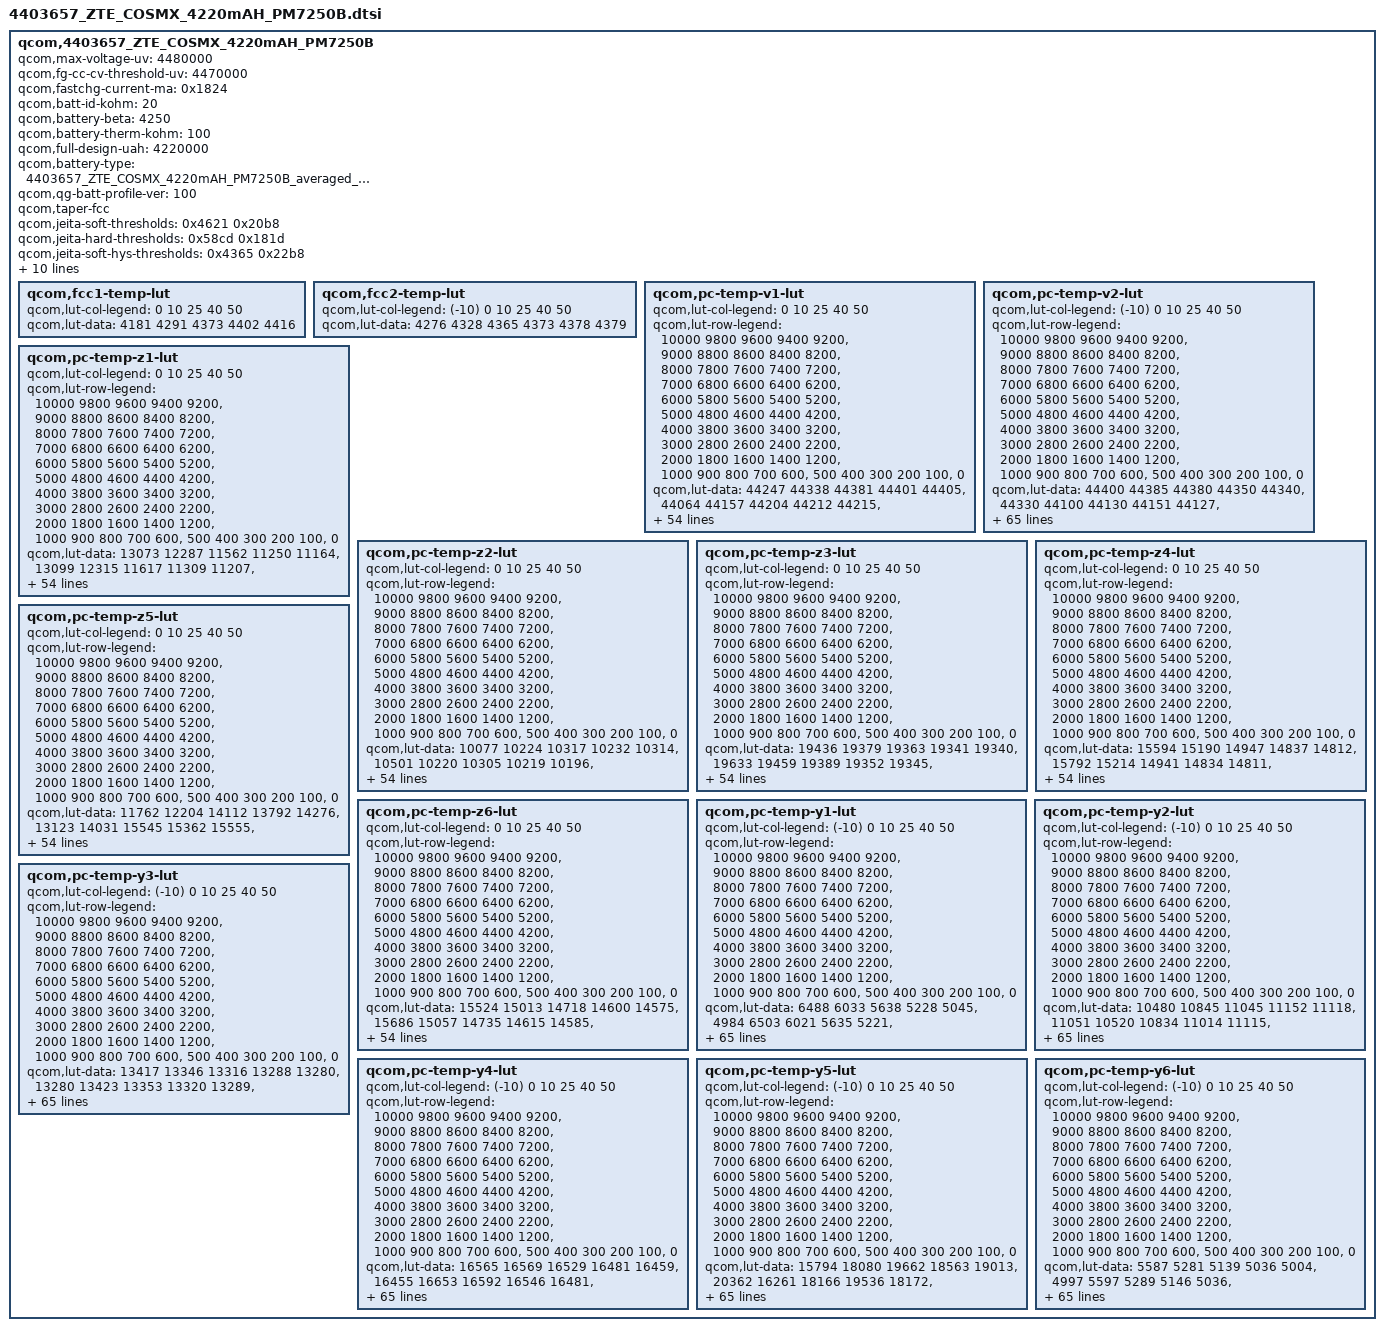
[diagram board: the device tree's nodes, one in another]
qcom,4403657_ZTE_COSMX_4220mAH_PM7250B {
	/* 4403657_ZTE_COSMX_4220mAH_PM7250B_averaged_MasterSlave_Feb19th2020 */
	qcom,max-voltage-uv = <4480000>;
	qcom,fg-cc-cv-threshold-uv = <4470000>;
	qcom,fastchg-current-ma = <0x1824>;
	qcom,batt-id-kohm = <20>;
	qcom,battery-beta = <4250>;
	qcom,battery-therm-kohm = <100>;
	qcom,full-design-uah = <4220000>;
	qcom,battery-type = "4403657_ZTE_COSMX_4220mAH_PM7250B_averaged_MasterSlave_Feb19th2020";
	qcom,qg-batt-profile-ver = <100>;
	qcom,taper-fcc;
	qcom,jeita-soft-thresholds = <0x4621 0x20b8>;
	qcom,jeita-hard-thresholds = <0x58cd 0x181d>;
	qcom,jeita-soft-hys-thresholds = <0x4365 0x22b8>;
	qcom,jeita-soft-fcc-ua = <2884000 1442000>;
	qcom,jeita-soft-fv-uv = <4480000 4100000>;
	qcom,ignore-shutdown-soc-secs = <36000>;
	qcom,shutdown_soc_threshold = <10>;
	qcom,jeita-fcc-ranges = <0  49  2060000
				50  149  2884000
				150 399  6180000
				399 419  4400000
				419 439  3000000
				439 449  1000000
				450 549  1442000>;

	qcom,jeita-fv-ranges = <0  49  4480000
				50  149  4480000
				150 449  4480000
				450 549  4100000>;

	qcom,step-chg-ranges = <3400000  4250000  6180000
				4251000  4350000  4120000
				4351000  4480000  2884000>;

	qcom,fcc1-temp-lut {
		qcom,lut-col-legend = <0 10 25 40 50>;
		qcom,lut-data = <4181 4291 4373 4402 4416>;
	};

	qcom,fcc2-temp-lut {
		qcom,lut-col-legend = <(-10) 0 10 25 40 50>;
		qcom,lut-data = <4276 4328 4365 4373 4378 4379>;
	};

	qcom,pc-temp-v1-lut {
		qcom,lut-col-legend = <0 10 25 40 50>;
		qcom,lut-row-legend = <10000 9800 9600 9400 9200>,
			<9000 8800 8600 8400 8200>,
			<8000 7800 7600 7400 7200>,
			<7000 6800 6600 6400 6200>,
			<6000 5800 5600 5400 5200>,
			<5000 4800 4600 4400 4200>,
			<4000 3800 3600 3400 3200>,
			<3000 2800 2600 2400 2200>,
			<2000 1800 1600 1400 1200>,
			<1000 900 800 700 600>,
			<500 400 300 200 100>,
			<0>;

		qcom,lut-data = <44247 44338 44381 44401 44405>,
			<44064 44157 44204 44212 44215>,
			<43852 43960 44014 44025 44028>,
			<43627 43758 43824 43834 43838>,
			<43399 43547 43616 43634 43644>,
			<43162 43321 43397 43418 43430>,
			<42920 43078 43164 43191 43205>,
			<42673 42831 42919 42951 42969>,
			<42425 42581 42670 42705 42726>,
			<42181 42330 42418 42454 42478>,
			<41942 42083 42166 42202 42225>,
			<41706 41840 41921 41956 41977>,
			<41474 41602 41679 41711 41730>,
			<41248 41370 41441 41472 41488>,
			<41031 41145 41209 41239 41251>,
			<40820 40929 40984 41012 41021>,
			<40610 40718 40767 40792 40797>,
			<40397 40511 40558 40580 40583>,
			<40196 40306 40360 40381 40383>,
			<40010 40109 40166 40189 40196>,
			<39835 39933 39966 39985 39997>,
			<39666 39747 39760 39766 39779>,
			<39507 39482 39541 39545 39556>,
			<39334 39171 39282 39310 39325>,
			<39116 38972 39056 39092 39106>,
			<38899 38855 38915 38935 38945>,
			<38748 38756 38805 38810 38818>,
			<38630 38658 38693 38695 38701>,
			<38542 38567 38583 38587 38590>,
			<38476 38483 38484 38487 38487>,
			<38423 38405 38397 38395 38393>,
			<38373 38336 38320 38311 38305>,
			<38328 38276 38252 38235 38228>,
			<38287 38222 38191 38167 38160>,
			<38254 38177 38136 38101 38089>,
			<38221 38137 38085 38040 38017>,
			<38188 38097 38036 37978 37944>,
			<38153 38060 37989 37918 37870>,
			<38105 38012 37936 37853 37792>,
			<38026 37930 37857 37767 37698>,
			<37925 37819 37747 37657 37587>,
			<37809 37699 37625 37534 37462>,
			<37669 37561 37485 37392 37316>,
			<37507 37401 37326 37239 37165>,
			<37346 37246 37173 37095 37029>,
			<37223 37142 37084 37018 36958>,
			<37181 37109 37055 36992 36932>,
			<37152 37088 37036 36974 36915>,
			<37125 37065 37015 36952 36892>,
			<37093 37028 36964 36885 36812>,
			<37017 36853 36732 36613 36522>,
			<36708 36436 36284 36149 36055>,
			<36200 35850 35688 35553 35457>,
			<35508 35014 34870 34733 34634>,
			<34372 33672 33586 33439 33333>,
			<30000 30000 30000 30000 30000>;
	};

	qcom,pc-temp-v2-lut {
		qcom,lut-col-legend = <(-10) 0 10 25 40 50>;
		qcom,lut-row-legend = <10000 9800 9600 9400 9200>,
			<9000 8800 8600 8400 8200>,
			<8000 7800 7600 7400 7200>,
			<7000 6800 6600 6400 6200>,
			<6000 5800 5600 5400 5200>,
			<5000 4800 4600 4400 4200>,
			<4000 3800 3600 3400 3200>,
			<3000 2800 2600 2400 2200>,
			<2000 1800 1600 1400 1200>,
			<1000 900 800 700 600>,
			<500 400 300 200 100>,
			<0>;

		qcom,lut-data = <44400 44385 44380 44350 44340>,
			<44330 44100 44130 44151 44127>,
			<44114 44103 43830 43892 43929>,
			<43908 43893 43881 43594 43675>,
			<43719 43697 43680 43669 43389>,
			<43476 43519 43491 43474 43463>,
			<43177 43264 43305 43273 43257>,
			<43247 42950 43028 43069 43038>,
			<43023 43015 42717 42784 42825>,
			<42795 42782 42776 42477 42538>,
			<42577 42546 42535 42531 42230>,
			<42289 42326 42293 42283 42281>,
			<41986 42046 42076 42043 42035>,
			<42033 41745 41807 41829 41796>,
			<41789 41787 41499 41572 41585>,
			<41552 41546 41544 41236 41343>,
			<41345 41312 41306 41304 40968>,
			<41113 41112 41079 41073 41071>,
			<40719 40872 40892 40854 40848>,
			<40844 40486 40623 40678 40635>,
			<40631 40624 40246 40365 40453>,
			<40423 40421 40414 39979 40091>,
			<40219 40220 40219 40215 39719>,
			<39830 39974 40009 40019 40018>,
			<39499 39596 39703 39785 39830>,
			<39834 39302 39380 39441 39556>,
			<39629 39637 39116 39188 39227>,
			<39313 39373 39382 38935 39014>,
			<39039 39067 39093 39101 38767>,
			<38854 38874 38878 38894 38902>,
			<38610 38705 38727 38731 38749>,
			<38756 38465 38567 38594 38602>,
			<38621 38628 38323 38439 38470>,
			<38484 38502 38507 38184 38319>,
			<38356 38377 38394 38397 38076>,
			<38204 38253 38276 38294 38294>,
			<38005 38089 38158 38183 38204>,
			<38201 37947 37994 38068 38099>,
			<38123 38117 37893 37921 37980>,
			<38023 38052 38045 37843 37861>,
			<37901 37952 37979 37970 37790>,
			<37816 37836 37885 37902 37886>,
			<37732 37780 37778 37818 37819>,
			<37794 37669 37738 37726 37743>,
			<37724 37689 37601 37692 37680>,
			<37662 37617 37571 37528 37636>,
			<37624 37578 37521 37468 37450>,
			<37565 37553 37493 37435 37380>,
			<37364 37474 37465 37404 37347>,
			<37294 37271 37345 37350 37306>,
			<37252 37201 37173 37206 37217>,
			<37181 37131 37074 37078 37067>,
			<37062 37036 36988 36930 36976>,
			<36918 36911 36911 36866 36813>,
			<36876 36814 36833 36871 36837>,
			<36786 36829 36775 36800 36855>,
			<36826 36774 36785 36739 36770>,
			<36837 36812 36758 36745 36698>,
			<36724 36803 36782 36727 36700>,
			<36649 36641 36707 36687 36610>,
			<36631 36535 36414 36382 36343>,
			<36237 36495 36232 35946 35863>,
			<35828 35715 36208 35642 35289>,
			<35177 35153 35025 35744 34749>,
			<34297 34203 34205 34068 34720>,
			<33312 32699 32820 32758 32588>,
			<34037 31812 29556 28046 27219>,
			<27150>;
	};

	qcom,pc-temp-z1-lut {
		qcom,lut-col-legend = <0 10 25 40 50>;
		qcom,lut-row-legend = <10000 9800 9600 9400 9200>,
			<9000 8800 8600 8400 8200>,
			<8000 7800 7600 7400 7200>,
			<7000 6800 6600 6400 6200>,
			<6000 5800 5600 5400 5200>,
			<5000 4800 4600 4400 4200>,
			<4000 3800 3600 3400 3200>,
			<3000 2800 2600 2400 2200>,
			<2000 1800 1600 1400 1200>,
			<1000 900 800 700 600>,
			<500 400 300 200 100>,
			<0>;

		qcom,lut-data = <13073 12287 11562 11250 11164>,
			<13099 12315 11617 11309 11207>,
			<13095 12302 11614 11314 11213>,
			<13088 12285 11604 11308 11212>,
			<13066 12269 11592 11303 11208>,
			<13025 12248 11578 11298 11206>,
			<12995 12216 11563 11293 11203>,
			<12963 12185 11549 11287 11200>,
			<12926 12156 11539 11283 11198>,
			<12889 12132 11531 11279 11196>,
			<12850 12115 11526 11276 11194>,
			<12811 12102 11521 11273 11193>,
			<12763 12095 11518 11271 11192>,
			<12736 12091 11514 11269 11192>,
			<12736 12088 11512 11269 11190>,
			<12737 12084 11509 11268 11190>,
			<12736 12081 11507 11268 11190>,
			<12729 12079 11506 11267 11191>,
			<12725 12078 11505 11267 11191>,
			<12735 12078 11506 11268 11192>,
			<12754 12087 11506 11268 11192>,
			<12767 12098 11508 11268 11192>,
			<12778 12103 11510 11268 11192>,
			<12783 12106 11513 11270 11194>,
			<12776 12110 11517 11273 11197>,
			<12767 12114 11522 11276 11200>,
			<12772 12120 11529 11281 11203>,
			<12793 12126 11534 11284 11207>,
			<12806 12133 11539 11288 11210>,
			<12809 12139 11543 11292 11212>,
			<12812 12146 11548 11295 11215>,
			<12824 12153 11553 11298 11217>,
			<12848 12162 11559 11302 11220>,
			<12861 12173 11565 11306 11223>,
			<12867 12183 11572 11310 11227>,
			<12874 12194 11580 11316 11231>,
			<12885 12208 11589 11321 11236>,
			<12904 12229 11597 11325 11239>,
			<12928 12249 11605 11329 11242>,
			<12969 12263 11613 11333 11246>,
			<13010 12275 11621 11338 11250>,
			<13033 12288 11629 11342 11253>,
			<13055 12301 11636 11345 11256>,
			<13102 12322 11643 11348 11259>,
			<13117 12350 11651 11352 11262>,
			<13150 12361 11666 11357 11264>,
			<13121 12361 11668 11357 11264>,
			<13161 12369 11673 11359 11265>,
			<13161 12379 11679 11363 11269>,
			<13147 12404 11690 11370 11275>,
			<13144 12405 11706 11377 11282>,
			<13202 12437 11716 11386 11289>,
			<13225 12448 11731 11398 11299>,
			<13273 12485 11757 11414 11314>,
			<13273 12485 11757 11414 11314>,
			<13273 12485 11757 11414 11314>;
	};

	qcom,pc-temp-z2-lut {
		qcom,lut-col-legend = <0 10 25 40 50>;
		qcom,lut-row-legend = <10000 9800 9600 9400 9200>,
			<9000 8800 8600 8400 8200>,
			<8000 7800 7600 7400 7200>,
			<7000 6800 6600 6400 6200>,
			<6000 5800 5600 5400 5200>,
			<5000 4800 4600 4400 4200>,
			<4000 3800 3600 3400 3200>,
			<3000 2800 2600 2400 2200>,
			<2000 1800 1600 1400 1200>,
			<1000 900 800 700 600>,
			<500 400 300 200 100>,
			<0>;

		qcom,lut-data = <10077 10224 10317 10232 10314>,
			<10501 10220 10305 10219 10196>,
			<10290 10260 10308 10241 10195>,
			<10104 10254 10367 10249 10164>,
			<10085 10237 10352 10270 10153>,
			<10070 10216 10324 10252 10161>,
			<10062 10184 10288 10231 10155>,
			<10056 10158 10245 10202 10068>,
			<10053 10137 10234 10180 10000>,
			<10054 10125 10235 10170 10002>,
			<10056 10130 10237 10163 10009>,
			<10056 10146 10241 10152 10017>,
			<10048 10161 10247 10134 10030>,
			<10043 10173 10252 10125 10041>,
			<10047 10190 10257 10097 10053>,
			<10056 10297 10264 10082 10066>,
			<10064 10442 10273 10098 10081>,
			<10072 10436 10282 10119 10097>,
			<10082 10318 10291 10129 10108>,
			<10092 10269 10302 10137 10118>,
			<10104 10278 10324 10167 10134>,
			<10117 10291 10361 10298 10169>,
			<10131 10318 10374 10377 10208>,
			<10150 10358 10355 10309 10265>,
			<10192 10365 10337 10224 10328>,
			<10233 10334 10338 10238 10315>,
			<10237 10306 10344 10293 10235>,
			<10233 10297 10344 10300 10160>,
			<10228 10292 10340 10226 10061>,
			<10217 10294 10335 10152 10001>,
			<10208 10303 10319 10108 10012>,
			<10207 10310 10306 10079 10034>,
			<10209 10313 10315 10087 10055>,
			<10210 10317 10342 10123 10083>,
			<10212 10324 10369 10162 10121>,
			<10214 10334 10401 10209 10177>,
			<10217 10345 10429 10257 10237>,
			<10220 10356 10452 10301 10296>,
			<10221 10364 10472 10342 10347>,
			<10222 10370 10493 10377 10368>,
			<10222 10375 10512 10413 10381>,
			<10213 10369 10515 10432 10388>,
			<10201 10346 10502 10448 10405>,
			<10203 10337 10497 10449 10401>,
			<10265 10345 10491 10444 10366>,
			<10385 10413 10447 10374 10339>,
			<10396 10412 10423 10386 10326>,
			<10358 10523 10413 10396 10353>,
			<10408 10713 10416 10417 10414>,
			<10335 10829 10480 10450 10431>,
			<10314 10729 10477 10375 10283>,
			<10212 10518 10407 10247 10152>,
			<10081 10282 10341 10179 10086>,
			<9899 10223 10277 10118 10015>,
			<9899 10223 10277 10118 10015>,
			<9899 10223 10277 10118 10015>;
	};

	qcom,pc-temp-z3-lut {
		qcom,lut-col-legend = <0 10 25 40 50>;
		qcom,lut-row-legend = <10000 9800 9600 9400 9200>,
			<9000 8800 8600 8400 8200>,
			<8000 7800 7600 7400 7200>,
			<7000 6800 6600 6400 6200>,
			<6000 5800 5600 5400 5200>,
			<5000 4800 4600 4400 4200>,
			<4000 3800 3600 3400 3200>,
			<3000 2800 2600 2400 2200>,
			<2000 1800 1600 1400 1200>,
			<1000 900 800 700 600>,
			<500 400 300 200 100>,
			<0>;

		qcom,lut-data = <19436 19379 19363 19341 19340>,
			<19633 19459 19389 19352 19345>,
			<19683 19523 19407 19365 19356>,
			<19713 19541 19430 19386 19370>,
			<19725 19549 19441 19404 19389>,
			<19732 19554 19447 19410 19397>,
			<19734 19558 19448 19413 19399>,
			<19730 19559 19450 19415 19399>,
			<19723 19556 19449 19416 19399>,
			<19713 19551 19446 19413 19397>,
			<19699 19545 19441 19407 19394>,
			<19690 19536 19434 19403 19393>,
			<19684 19526 19427 19399 19391>,
			<19677 19515 19424 19395 19390>,
			<19666 19508 19421 19391 19388>,
			<19652 19512 19419 19387 19385>,
			<19645 19521 19416 19385 19383>,
			<19640 19517 19414 19382 19380>,
			<19637 19498 19410 19379 19375>,
			<19635 19490 19407 19375 19368>,
			<19632 19490 19409 19375 19365>,
			<19631 19491 19417 19380 19368>,
			<19630 19504 19420 19384 19370>,
			<19630 19531 19413 19378 19373>,
			<19649 19537 19406 19370 19376>,
			<19675 19522 19405 19381 19385>,
			<19677 19509 19405 19414 19408>,
			<19670 19506 19409 19423 19415>,
			<19663 19504 19431 19416 19408>,
			<19655 19505 19441 19408 19399>,
			<19648 19510 19437 19401 19393>,
			<19644 19513 19432 19394 19387>,
			<19641 19513 19426 19388 19379>,
			<19639 19513 19420 19383 19370>,
			<19637 19513 19416 19378 19362>,
			<19635 19511 19414 19370 19354>,
			<19633 19509 19412 19365 19350>,
			<19631 19505 19407 19362 19350>,
			<19628 19501 19403 19361 19351>,
			<19623 19499 19401 19361 19352>,
			<19617 19495 19399 19362 19355>,
			<19609 19492 19397 19364 19358>,
			<19599 19486 19395 19366 19362>,
			<19590 19481 19394 19367 19363>,
			<19556 19468 19392 19367 19361>,
			<19494 19438 19373 19349 19346>,
			<19478 19432 19371 19346 19342>,
			<19375 19372 19363 19338 19333>,
			<19325 19328 19360 19334 19325>,
			<19317 19313 19354 19334 19325>,
			<19311 19325 19356 19353 19344>,
			<19321 19349 19363 19359 19351>,
			<19342 19374 19369 19358 19349>,
			<19379 19462 19372 19360 19355>,
			<19379 19462 19372 19360 19355>,
			<19379 19462 19372 19360 19355>;
	};

	qcom,pc-temp-z4-lut {
		qcom,lut-col-legend = <0 10 25 40 50>;
		qcom,lut-row-legend = <10000 9800 9600 9400 9200>,
			<9000 8800 8600 8400 8200>,
			<8000 7800 7600 7400 7200>,
			<7000 6800 6600 6400 6200>,
			<6000 5800 5600 5400 5200>,
			<5000 4800 4600 4400 4200>,
			<4000 3800 3600 3400 3200>,
			<3000 2800 2600 2400 2200>,
			<2000 1800 1600 1400 1200>,
			<1000 900 800 700 600>,
			<500 400 300 200 100>,
			<0>;

		qcom,lut-data = <15594 15190 14947 14837 14812>,
			<15792 15214 14941 14834 14811>,
			<15762 15289 14877 14795 14779>,
			<15691 15229 14930 14806 14760>,
			<15578 15103 14895 14827 14814>,
			<15413 15021 14839 14793 14788>,
			<15286 14957 14805 14766 14765>,
			<15192 14908 14779 14745 14746>,
			<15116 14870 14758 14729 14732>,
			<15058 14839 14739 14720 14725>,
			<15011 14813 14728 14713 14720>,
			<14968 14790 14724 14709 14715>,
			<14927 14781 14721 14706 14710>,
			<14894 14779 14718 14704 14706>,
			<14868 14776 14713 14700 14702>,
			<14848 14756 14709 14697 14698>,
			<14841 14731 14705 14693 14695>,
			<14839 14731 14702 14688 14692>,
			<14836 14749 14700 14684 14688>,
			<14826 14756 14699 14681 14683>,
			<14813 14750 14701 14682 14683>,
			<14805 14744 14711 14700 14701>,
			<14800 14776 14729 14726 14727>,
			<14798 14854 14796 14774 14760>,
			<14821 14876 14851 14820 14791>,
			<14859 14872 14842 14803 14781>,
			<14882 14865 14818 14745 14733>,
			<14899 14853 14790 14719 14711>,
			<14904 14836 14753 14712 14706>,
			<14900 14820 14734 14708 14703>,
			<14892 14804 14728 14705 14700>,
			<14884 14792 14726 14703 14697>,
			<14874 14785 14725 14700 14693>,
			<14865 14780 14724 14696 14689>,
			<14854 14776 14724 14696 14688>,
			<14843 14773 14726 14699 14689>,
			<14831 14770 14727 14702 14691>,
			<14819 14765 14727 14704 14694>,
			<14807 14761 14727 14705 14696>,
			<14795 14757 14727 14707 14700>,
			<14784 14753 14729 14712 14704>,
			<14772 14744 14728 14712 14705>,
			<14760 14727 14716 14707 14705>,
			<14742 14714 14708 14705 14705>,
			<14721 14696 14699 14704 14707>,
			<14721 14670 14665 14670 14667>,
			<14735 14669 14658 14664 14661>,
			<14849 14726 14651 14652 14650>,
			<14900 14769 14640 14635 14634>,
			<14905 14780 14640 14632 14631>,
			<14900 14769 14657 14647 14655>,
			<14897 14754 14660 14658 14669>,
			<14893 14739 14659 14662 14676>,
			<14884 14681 14663 14663 14671>,
			<14884 14681 14663 14663 14671>,
			<14884 14681 14663 14663 14671>;
	};

	qcom,pc-temp-z5-lut {
		qcom,lut-col-legend = <0 10 25 40 50>;
		qcom,lut-row-legend = <10000 9800 9600 9400 9200>,
			<9000 8800 8600 8400 8200>,
			<8000 7800 7600 7400 7200>,
			<7000 6800 6600 6400 6200>,
			<6000 5800 5600 5400 5200>,
			<5000 4800 4600 4400 4200>,
			<4000 3800 3600 3400 3200>,
			<3000 2800 2600 2400 2200>,
			<2000 1800 1600 1400 1200>,
			<1000 900 800 700 600>,
			<500 400 300 200 100>,
			<0>;

		qcom,lut-data = <11762 12204 14112 13792 14276>,
			<13123 14031 15545 15362 15555>,
			<13705 15140 17327 17164 17445>,
			<14150 15416 16950 18771 20009>,
			<14451 15731 17438 18843 19176>,
			<14679 16105 18243 20073 20614>,
			<14961 16544 18785 21098 21701>,
			<15354 16975 19256 21969 22307>,
			<15740 17364 19853 22713 22841>,
			<16016 17770 20764 23357 23360>,
			<16260 18352 21263 23874 23893>,
			<16629 19008 20973 24101 24610>,
			<17281 19147 20567 24059 25538>,
			<17951 18901 20636 23977 26489>,
			<18516 18721 21074 23735 27455>,
			<19031 20490 21513 23787 28461>,
			<19364 23196 21950 24430 29774>,
			<19721 23134 22329 25217 30917>,
			<20183 21040 22545 25700 30754>,
			<20889 20239 22755 26080 29740>,
			<21881 21127 24114 26864 29315>,
			<23065 22836 28131 28850 29471>,
			<24574 28771 29519 29944 29567>,
			<27014 39450 25193 24569 25479>,
			<36108 41399 20503 17802 19319>,
			<46334 32631 18699 18455 19612>,
			<46585 25447 17512 21954 23352>,
			<42057 23985 18118 23838 25391>,
			<37814 23186 21913 24697 26031>,
			<34532 23450 24864 25260 26517>,
			<32038 25096 26279 25576 27161>,
			<30989 26830 27327 25854 27686>,
			<30327 28436 28113 26546 27492>,
			<30145 29936 28752 27629 26572>,
			<30219 31211 29664 27876 25843>,
			<30368 32319 31031 27335 25279>,
			<30744 32757 31641 26851 25000>,
			<31473 32873 30792 26701 25796>,
			<32062 32894 29541 26575 26970>,
			<32605 32889 28762 26223 26874>,
			<32929 32829 28137 25619 26130>,
			<31645 32448 27933 25590 26073>,
			<29306 31451 28089 26811 27984>,
			<28563 30829 28332 27132 28391>,
			<27273 30122 28696 26876 27403>,
			<20930 27125 27324 24353 25489>,
			<18203 24240 26900 23278 23088>,
			<12902 15844 24569 22647 22065>,
			<11767 12564 25127 26087 24523>,
			<11619 12167 23543 27538 30992>,
			<11589 12620 20940 27556 27354>,
			<11735 13490 20563 24843 22021>,
			<11938 14508 21205 21594 18795>,
			<12355 30359 20722 19485 18231>,
			<12355 30359 20722 19485 18231>,
			<12355 30359 20722 19485 18231>;
	};

	qcom,pc-temp-z6-lut {
		qcom,lut-col-legend = <0 10 25 40 50>;
		qcom,lut-row-legend = <10000 9800 9600 9400 9200>,
			<9000 8800 8600 8400 8200>,
			<8000 7800 7600 7400 7200>,
			<7000 6800 6600 6400 6200>,
			<6000 5800 5600 5400 5200>,
			<5000 4800 4600 4400 4200>,
			<4000 3800 3600 3400 3200>,
			<3000 2800 2600 2400 2200>,
			<2000 1800 1600 1400 1200>,
			<1000 900 800 700 600>,
			<500 400 300 200 100>,
			<0>;

		qcom,lut-data = <15524 15013 14718 14600 14575>,
			<15686 15057 14735 14615 14585>,
			<15668 15113 14716 14605 14579>,
			<15634 15087 14748 14621 14578>,
			<15580 15030 14735 14636 14609>,
			<15491 14989 14713 14626 14603>,
			<15416 14955 14698 14618 14597>,
			<15356 14926 14685 14610 14589>,
			<15304 14901 14674 14602 14582>,
			<15260 14879 14663 14596 14577>,
			<15222 14860 14654 14590 14574>,
			<15188 14843 14648 14585 14570>,
			<15156 14831 14643 14581 14567>,
			<15129 14823 14638 14577 14564>,
			<15107 14817 14634 14573 14561>,
			<15089 14810 14631 14569 14558>,
			<15083 14804 14627 14566 14555>,
			<15081 14801 14624 14563 14552>,
			<15079 14798 14621 14559 14547>,
			<15073 14797 14619 14555 14541>,
			<15067 14796 14620 14555 14540>,
			<15066 14795 14628 14566 14548>,
			<15067 14816 14640 14579 14561>,
			<15070 14865 14666 14598 14578>,
			<15093 14878 14686 14614 14594>,
			<15123 14871 14682 14613 14594>,
			<15135 14862 14673 14607 14588>,
			<15142 14856 14667 14602 14582>,
			<15144 14850 14663 14596 14577>,
			<15140 14846 14660 14590 14572>,
			<15136 14844 14656 14586 14567>,
			<15133 14842 14653 14581 14563>,
			<15130 14841 14650 14577 14558>,
			<15127 14840 14647 14573 14551>,
			<15125 14841 14647 14570 14546>,
			<15123 14841 14647 14568 14543>,
			<15124 14841 14647 14566 14541>,
			<15125 14841 14646 14566 14542>,
			<15126 14841 14645 14565 14543>,
			<15130 14841 14645 14566 14545>,
			<15133 14842 14646 14570 14548>,
			<15133 14840 14646 14571 14551>,
			<15134 14835 14641 14571 14554>,
			<15137 14832 14638 14571 14555>,
			<15132 14825 14635 14571 14555>,
			<15119 14806 14614 14547 14530>,
			<15119 14803 14610 14543 14525>,
			<15117 14798 14604 14534 14516>,
			<15117 14797 14599 14526 14505>,
			<15122 14799 14599 14524 14504>,
			<15129 14807 14609 14543 14526>,
			<15145 14819 14618 14553 14539>,
			<15169 14835 14624 14557 14543>,
			<15201 14869 14634 14563 14549>,
			<15201 14869 14634 14563 14549>,
			<15201 14869 14634 14563 14549>;
	};

	qcom,pc-temp-y1-lut {
		qcom,lut-col-legend = <(-10) 0 10 25 40 50>;
		qcom,lut-row-legend = <10000 9800 9600 9400 9200>,
			<9000 8800 8600 8400 8200>,
			<8000 7800 7600 7400 7200>,
			<7000 6800 6600 6400 6200>,
			<6000 5800 5600 5400 5200>,
			<5000 4800 4600 4400 4200>,
			<4000 3800 3600 3400 3200>,
			<3000 2800 2600 2400 2200>,
			<2000 1800 1600 1400 1200>,
			<1000 900 800 700 600>,
			<500 400 300 200 100>,
			<0>;

		qcom,lut-data = <6488 6033 5638 5228 5045>,
			<4984 6503 6021 5635 5221>,
			<5041 4982 6523 6011 5631>,
			<5215 5037 4980 6543 6004>,
			<5626 5209 5033 4978 6558>,
			<6001 5621 5203 5030 4976>,
			<6563 6001 5616 5198 5028>,
			<4975 6562 6006 5609 5193>,
			<5026 4974 6560 6011 5603>,
			<5189 5025 4973 6560 6012>,
			<5598 5186 5024 4972 6560>,
			<6012 5594 5183 5022 4972>,
			<6560 6011 5593 5180 5021>,
			<4971 6556 6004 5593 5178>,
			<5020 4971 6552 6000 5592>,
			<5176 5020 4970 6552 6000>,
			<5589 5174 5019 4970 6552>,
			<6002 5585 5172 5018 4971>,
			<6552 6004 5581 5171 5018>,
			<4971 6553 6006 5578 5171>,
			<5018 4971 6555 6009 5577>,
			<5171 5019 4971 6565 6014>,
			<5577 5171 5019 4972 6575>,
			<6017 5578 5171 5019 4972>,
			<6576 6017 5581 5172 5020>,
			<4973 6575 6017 5585 5173>,
			<5021 4973 6575 6018 5585>,
			<5175 5021 4973 6578 6023>,
			<5585 5176 5022 4973 6581>,
			<6025 5587 5178 5022 4973>,
			<6577 6025 5590 5180 5024>,
			<4975 6572 6026 5593 5183>,
			<5026 4976 6571 6029 5596>,
			<5186 5028 4978 6574 6034>,
			<5599 5189 5031 4980 6575>,
			<6037 5603 5193 5033 4982>,
			<6569 6036 5610 5197 5035>,
			<4983 6562 6036 5615 5201>,
			<5037 4986 6560 6037 5620>,
			<5205 5040 4989 6559 6039>,
			<5623 5209 5043 4991 6557>,
			<6039 5625 5213 5045 4992>,
			<6552 6037 5626 5217 5048>,
			<4993 6547 6037 5629 5220>,
			<5050 4994 6544 6043 5633>,
			<5222 5051 4996 6541 6048>,
			<5637 5224 5052 4997 6536>,
			<6050 5640 5226 5053 4999>,
			<6525 6051 5644 5229 5054>,
			<5000 6523 6050 5653 5232>,
			<5057 5002 6522 6050 5670>,
			<5237 5058 5005 6536 6099>,
			<5682 5243 5062 5007 6607>,
			<6098 5693 5251 5067 5011>,
			<6583 6095 5702 5260 5071>,
			<5013 6619 6091 5713 5263>,
			<5071 5013 6628 6096 5715>,
			<5265 5070 5013 6637 6100>,
			<5716 5264 5070 5014 6622>,
			<6095 5710 5268 5071 5014>,
			<6618 6087 5705 5271 5073>,
			<5017 6695 6099 5702 5285>,
			<5078 5021 6837 6184 5755>,
			<5310 5086 5028 6980 6403>,
			<5835 5347 5098 5037 6980>,
			<6403 5835 5347 5098 5037>,
			<6980 6403 5835 5347 5098>,
			<5037>;
	};

	qcom,pc-temp-y2-lut {
		qcom,lut-col-legend = <(-10) 0 10 25 40 50>;
		qcom,lut-row-legend = <10000 9800 9600 9400 9200>,
			<9000 8800 8600 8400 8200>,
			<8000 7800 7600 7400 7200>,
			<7000 6800 6600 6400 6200>,
			<6000 5800 5600 5400 5200>,
			<5000 4800 4600 4400 4200>,
			<4000 3800 3600 3400 3200>,
			<3000 2800 2600 2400 2200>,
			<2000 1800 1600 1400 1200>,
			<1000 900 800 700 600>,
			<500 400 300 200 100>,
			<0>;

		qcom,lut-data = <10480 10845 11045 11152 11118>,
			<11051 10520 10834 11014 11115>,
			<11057 10990 10561 10823 10983>,
			<11059 10978 10921 10600 10812>,
			<10951 10998 10899 10855 10633>,
			<10803 10919 10947 10836 10803>,
			<10658 10795 10885 10921 10805>,
			<10774 10675 10780 10847 10902>,
			<10790 10760 10690 10769 10817>,
			<10887 10777 10747 10706 10771>,
			<10800 10870 10757 10725 10721>,
			<10779 10790 10849 10732 10701>,
			<10734 10790 10791 10837 10713>,
			<10684 10744 10808 10805 10828>,
			<10696 10667 10756 10831 10825>,
			<10824 10687 10661 10788 10864>,
			<10857 10825 10687 10665 10829>,
			<10901 10896 10830 10689 10668>,
			<10851 10938 10931 10844 10690>,
			<10657 10865 10975 10968 10876>,
			<10696 10638 10870 10987 11023>,
			<10927 10717 10636 10860 10989>,
			<11107 11017 10775 10648 10847>,
			<10990 11144 11104 10859 10674>,
			<10842 10990 11113 11200 11040>,
			<10850 10839 10989 11077 11266>,
			<11184 11013 10834 10990 11075>,
			<11242 11129 10996 10825 10993>,
			<11079 11177 11007 10951 10814>,
			<10996 11088 11158 10984 10946>,
			<10799 11001 11111 11164 11004>,
			<10970 10780 11004 11126 11171>,
			<11034 10998 10756 11002 11124>,
			<11188 11085 11038 10725 10994>,
			<11121 11215 11141 11089 10679>,
			<10985 11123 11237 11174 11141>,
			<10495 10973 11128 11259 11199>,
			<11194 10276 10960 11128 11278>,
			<11232 11230 10120 10950 11116>,
			<11299 11284 11259 9857 10938>,
			<11103 11309 11310 11275 9739>,
			<10921 11094 11295 11281 11282>,
			<9711 10897 11084 11266 11233>,
			<11286 9694 10868 11073 11232>,
			<11192 11272 9684 10826 11058>,
			<11189 11149 11227 9677 10773>,
			<11037 11166 11127 11188 9672>,
			<10713 11002 11161 11105 11152>,
			<9669 10605 10952 11156 11091>,
			<11124 9666 9992 10886 11154>,
			<11081 11098 9665 9830 10825>,
			<11158 11111 11103 9663 9811>,
			<10790 11128 11125 11124 9662>,
			<9721 10683 11074 11073 10959>,
			<9660 9682 10500 11056 10911>,
			<10817 9659 9674 10334 11026>,
			<10880 10799 9657 9669 10161>,
			<11034 10918 10778 9656 9664>,
			<9950 11051 10966 10801 9653>,
			<9660 9771 11069 10940 10807>,
			<9651 9655 9691 10995 10897>,
			<10775 9649 9651 9663 10955>,
			<10802 10706 9648 9649 9653>,
			<10867 10692 10589 9648 9648>,
			<9650 10766 10570 10437 9648>,
			<9648 9650 10766 10570 10437>,
			<9648 9648 9650 10766 10570>,
			<10437>;
	};

	qcom,pc-temp-y3-lut {
		qcom,lut-col-legend = <(-10) 0 10 25 40 50>;
		qcom,lut-row-legend = <10000 9800 9600 9400 9200>,
			<9000 8800 8600 8400 8200>,
			<8000 7800 7600 7400 7200>,
			<7000 6800 6600 6400 6200>,
			<6000 5800 5600 5400 5200>,
			<5000 4800 4600 4400 4200>,
			<4000 3800 3600 3400 3200>,
			<3000 2800 2600 2400 2200>,
			<2000 1800 1600 1400 1200>,
			<1000 900 800 700 600>,
			<500 400 300 200 100>,
			<0>;

		qcom,lut-data = <13417 13346 13316 13288 13280>,
			<13280 13423 13353 13320 13289>,
			<13282 13281 13435 13361 13324>,
			<13290 13283 13282 13449 13369>,
			<13328 13291 13284 13282 13461>,
			<13375 13331 13293 13285 13283>,
			<13464 13379 13333 13294 13286>,
			<13284 13464 13381 13335 13295>,
			<13287 13284 13464 13382 13336>,
			<13296 13287 13285 13464 13381>,
			<13338 13297 13288 13285 13462>,
			<13380 13339 13298 13288 13286>,
			<13460 13378 13340 13299 13288>,
			<13287 13459 13378 13339 13300>,
			<13289 13287 13457 13377 13338>,
			<13301 13290 13287 13451 13380>,
			<13336 13302 13291 13288 13442>,
			<13383 13334 13304 13291 13288>,
			<13436 13382 13335 13306 13293>,
			<13288 13431 13378 13337 13308>,
			<13296 13289 13426 13373 13338>,
			<13308 13297 13289 13421 13366>,
			<13338 13305 13297 13292 13416>,
			<13360 13337 13304 13297 13293>,
			<13411 13356 13331 13304 13297>,
			<13294 13407 13352 13323 13304>,
			<13297 13294 13403 13350 13319>,
			<13301 13292 13290 13399 13348>,
			<13316 13294 13285 13282 13397>,
			<13347 13315 13290 13282 13280>,
			<13395 13346 13315 13288 13282>,
			<13280 13393 13345 13314 13288>,
			<13282 13280 13388 13344 13314>,
			<13288 13281 13280 13376 13343>,
			<13313 13288 13281 13280 13369>,
			<13341 13313 13288 13280 13279>,
			<13369 13339 13313 13288 13280>,
			<13278 13370 13337 13313 13288>,
			<13280 13277 13375 13336 13312>,
			<13288 13280 13278 13393 13335>,
			<13311 13288 13280 13278 13411>,
			<13336 13311 13289 13280 13279>,
			<13431 13341 13311 13289 13280>,
			<13279 13455 13345 13311 13289>,
			<13280 13279 13490 13348 13313>,
			<13288 13280 13278 13535 13352>,
			<13315 13288 13280 13278 13588>,
			<13357 13317 13288 13281 13279>,
			<13654 13360 13319 13289 13281>,
			<13280 13724 13359 13319 13289>,
			<13282 13281 13804 13368 13320>,
			<13289 13281 13280 13885 13371>,
			<13316 13286 13279 13277 13961>,
			<13406 13319 13286 13278 13277>,
			<14140 13465 13326 13291 13285>,
			<13283 14268 13518 13330 13293>,
			<13287 13286 14428 13596 13340>,
			<13296 13290 13287 14665 13728>,
			<13355 13299 13291 13289 15093>,
			<13968 13388 13301 13290 13287>,
			<16327 14502 13464 13297 13286>,
			<13284 19450 16643 13747 13300>,
			<13287 13285 28052 23895 15634>,
			<13307 13292 13290 60245 65535>,
			<24470 13320 13298 13300 60245>,
			<65535 24470 13320 13298 13300>,
			<60245 65535 24470 13320 13298>,
			<13300>;
	};

	qcom,pc-temp-y4-lut {
		qcom,lut-col-legend = <(-10) 0 10 25 40 50>;
		qcom,lut-row-legend = <10000 9800 9600 9400 9200>,
			<9000 8800 8600 8400 8200>,
			<8000 7800 7600 7400 7200>,
			<7000 6800 6600 6400 6200>,
			<6000 5800 5600 5400 5200>,
			<5000 4800 4600 4400 4200>,
			<4000 3800 3600 3400 3200>,
			<3000 2800 2600 2400 2200>,
			<2000 1800 1600 1400 1200>,
			<1000 900 800 700 600>,
			<500 400 300 200 100>,
			<0>;

		qcom,lut-data = <16565 16569 16529 16481 16459>,
			<16455 16653 16592 16546 16481>,
			<16459 16457 16761 16638 16566>,
			<16482 16460 16460 16869 16690>,
			<16585 16482 16461 16462 16956>,
			<16731 16598 16483 16461 16463>,
			<17001 16743 16600 16483 16462>,
			<16464 17024 16744 16596 16482>,
			<16462 16463 17035 16745 16592>,
			<16482 16462 16463 17035 16750>,
			<16592 16482 16462 16462 17034>,
			<16759 16593 16483 16464 16462>,
			<17031 16771 16595 16485 16465>,
			<16463 17026 16787 16606 16489>,
			<16467 16464 17018 16798 16620>,
			<16494 16470 16466 17007 16802>,
			<16640 16500 16473 16469 16992>,
			<16804 16663 16506 16477 16472>,
			<16981 16803 16687 16516 16481>,
			<16475 16972 16798 16710 16530>,
			<16485 16481 16957 16787 16713>,
			<16553 16493 16487 16895 16747>,
			<16703 16592 16509 16495 16823>,
			<16702 16686 16609 16529 16508>,
			<16793 16669 16636 16599 16562>,
			<16540 16775 16641 16580 16583>,
			<16586 16566 16754 16625 16556>,
			<16548 16553 16538 16731 16615>,
			<16541 16492 16484 16480 16707>,
			<16605 16533 16478 16466 16465>,
			<16680 16596 16527 16477 16464>,
			<16462 16653 16587 16525 16476>,
			<16463 16462 16634 16579 16524>,
			<16478 16465 16463 16620 16571>,
			<16523 16481 16469 16465 16614>,
			<16559 16523 16484 16475 16470>,
			<16629 16539 16524 16489 16483>,
			<16478 16652 16529 16523 16495>,
			<16492 16487 16667 16531 16514>,
			<16501 16504 16499 16686 16534>,
			<16507 16505 16510 16506 16700>,
			<16541 16506 16506 16510 16507>,
			<16712 16559 16506 16506 16509>,
			<16508 16719 16577 16509 16502>,
			<16501 16501 16721 16599 16523>,
			<16488 16481 16484 16723 16615>,
			<16535 16480 16475 16480 16722>,
			<16623 16546 16477 16476 16482>,
			<16717 16629 16550 16478 16479>,
			<16488 16715 16652 16550 16482>,
			<16484 16495 16713 16640 16541>,
			<16475 16476 16481 16703 16598>,
			<16513 16457 16454 16456 16692>,
			<16594 16514 16449 16439 16437>,
			<16697 16610 16533 16463 16455>,
			<16463 16704 16622 16552 16477>,
			<16481 16499 16716 16635 16576>,
			<16500 16518 16540 16729 16659>,
			<16609 16535 16556 16575 16750>,
			<16694 16670 16556 16563 16566>,
			<16888 16730 16691 16507 16483>,
			<16483 17304 16894 16710 16503>,
			<16477 16481 18409 18252 16886>,
			<16529 16479 16479 25735 30518>,
			<19756 16586 16490 16488 25735>,
			<30518 19756 16586 16490 16488>,
			<25735 30518 19756 16586 16490>,
			<16488>;
	};

	qcom,pc-temp-y5-lut {
		qcom,lut-col-legend = <(-10) 0 10 25 40 50>;
		qcom,lut-row-legend = <10000 9800 9600 9400 9200>,
			<9000 8800 8600 8400 8200>,
			<8000 7800 7600 7400 7200>,
			<7000 6800 6600 6400 6200>,
			<6000 5800 5600 5400 5200>,
			<5000 4800 4600 4400 4200>,
			<4000 3800 3600 3400 3200>,
			<3000 2800 2600 2400 2200>,
			<2000 1800 1600 1400 1200>,
			<1000 900 800 700 600>,
			<500 400 300 200 100>,
			<0>;

		qcom,lut-data = <15794 18080 19662 18563 19013>,
			<20362 16261 18166 19536 18172>,
			<19231 20323 16739 18170 19322>,
			<17762 19267 20280 17185 18108>,
			<19039 17377 19201 20220 17559>,
			<17996 18707 17065 19117 20130>,
			<17819 17843 18338 16868 19080>,
			<19994 17984 17553 17884 16756>,
			<18911 19795 18125 17184 17436>,
			<16650 18668 19650 18275 16716>,
			<17084 16511 18181 19462 18432>,
			<16240 16744 16342 17496 19136>,
			<18703 16166 16248 16087 17129>,
			<18827 19308 16275 15548 15671>,
			<16899 18350 19694 16479 15065>,
			<15353 16660 17844 19233 17470>,
			<14754 15259 16187 17321 18496>,
			<18731 14586 15213 15848 16791>,
			<18716 19297 15004 15065 16055>,
			<16177 20237 19666 16217 14914>,
			<16440 15588 21199 20065 17987>,
			<14818 16294 15402 21455 20633>,
			<21075 14785 15346 15329 21588>,
			<20985 22508 15146 14968 15382>,
			<21597 20969 22261 19269 16763>,
			<16204 21573 20914 21842 23363>,
			<18703 17255 21587 21029 21347>,
			<22730 18988 17983 21722 21438>,
			<20783 20776 18967 18672 21916>,
			<21907 20739 19627 18909 18939>,
			<22298 22525 21383 18836 18811>,
			<19079 22766 23070 21967 18469>,
			<18655 19075 22090 23407 22186>,
			<18834 18114 18600 18246 23700>,
			<22385 19360 17458 17868 15552>,
			<23613 22886 19435 17082 16916>,
			<14739 22549 23710 19443 16803>,
			<15704 14253 21376 24124 19591>,
			<16817 15478 14078 20158 24337>,
			<20441 17374 15854 14014 19198>,
			<24436 21535 18123 16444 14038>,
			<19408 23779 22986 19050 17632>,
			<14069 20292 22712 24250 20160>,
			<19123 14107 20860 22357 24408>,
			<21449 20331 14241 21177 22153>,
			<24420 22831 21406 14440 21343>,
			<22040 24301 23172 21875 14503>,
			<21305 21998 23527 23087 22089>,
			<14445 21067 21798 22986 22638>,
			<22396 14188 16685 21029 22477>,
			<21761 22735 13720 15157 20883>,
			<23226 22132 21845 13607 14824>,
			<20241 22917 24239 24624 13263>,
			<14522 19566 21594 20334 20086>,
			<13354 14096 18876 21614 19890>,
			<18268 13362 13966 17600 19871>,
			<18289 16226 13418 14062 17096>,
			<19309 16924 15105 13728 14021>,
			<15946 18515 16218 14930 13807>,
			<14323 14972 18702 15723 14579>,
			<12788 14241 14935 19512 17177>,
			<16257 11151 12538 14499 20932>,
			<17017 15579 9963 10022 12730>,
			<22174 18545 16271 9348 9337>,
			<9663 22199 20771 22159 9348>,
			<9337 9663 22199 20771 22159>,
			<9348 9337 9663 22199 20771>,
			<22159>;
	};

	qcom,pc-temp-y6-lut {
		qcom,lut-col-legend = <(-10) 0 10 25 40 50>;
		qcom,lut-row-legend = <10000 9800 9600 9400 9200>,
			<9000 8800 8600 8400 8200>,
			<8000 7800 7600 7400 7200>,
			<7000 6800 6600 6400 6200>,
			<6000 5800 5600 5400 5200>,
			<5000 4800 4600 4400 4200>,
			<4000 3800 3600 3400 3200>,
			<3000 2800 2600 2400 2200>,
			<2000 1800 1600 1400 1200>,
			<1000 900 800 700 600>,
			<500 400 300 200 100>,
			<0>;

		qcom,lut-data = <5587 5281 5139 5036 5004>,
			<4997 5597 5289 5146 5036>,
			<5005 4998 5621 5301 5153>,
			<5036 5006 4999 5648 5314>,
			<5159 5037 5006 5000 5669>,
			<5324 5162 5037 5007 5001>,
			<5676 5327 5163 5037 5008>,
			<5002 5676 5326 5160 5038>,
			<5008 5002 5676 5324 5158>,
			<5038 5009 5002 5673 5323>,
			<5158 5039 5009 5003 5667>,
			<5322 5157 5039 5010 5003>,
			<5661 5322 5158 5040 5011>,
			<5004 5656 5323 5159 5042>,
			<5012 5005 5651 5325 5161>,
			<5044 5013 5006 5641 5327>,
			<5164 5046 5014 5007 5630>,
			<5328 5168 5049 5016 5008>,
			<5624 5327 5175 5053 5018>,
			<5009 5621 5322 5182 5058>,
			<5021 5011 5615 5315 5183>,
			<5064 5025 5014 5597 5300>,
			<5180 5073 5030 5017 5578>,
			<5284 5175 5077 5035 5022>,
			<5570 5272 5156 5074 5044>,
			<5031 5565 5262 5135 5069>,
			<5050 5038 5562 5258 5126>,
			<5057 5038 5027 5559 5255>,
			<5120 5036 5012 5005 5557>,
			<5254 5117 5030 5005 4999>,
			<5557 5252 5116 5028 5004>,
			<4998 5558 5251 5116 5028>,
			<5004 4998 5558 5252 5116>,
			<5029 5004 4998 5560 5252>,
			<5117 5030 5005 4999 5562>,
			<5252 5118 5032 5006 5000>,
			<5575 5250 5120 5033 5009>,
			<5001 5596 5249 5121 5035>,
			<5011 5003 5619 5252 5120>,
			<5037 5015 5007 5647 5259>,
			<5119 5039 5017 5010 5678>,
			<5270 5120 5041 5017 5010>,
			<5713 5285 5122 5041 5017>,
			<5011 5753 5304 5126 5040>,
			<5015 5009 5798 5327 5134>,
			<5036 5009 5004 5850 5353>,
			<5142 5035 5008 5002 5906>,
			<5381 5151 5034 5009 5004>,
			<5967 5410 5160 5035 5011>,
			<5007 6033 5436 5168 5037>,
			<5012 5010 6106 5470 5173>,
			<5036 5010 5005 6189 5475>,
			<5166 5029 5003 4996 6265>,
			<5536 5183 5028 4998 4991>,
			<6420 5633 5219 5037 5008>,
			<5004 6532 5703 5247 5043>,
			<5018 5016 6678 5795 5289>,
			<5053 5030 5029 6890 5934>,
			<5346 5065 5042 5041 7263>,
			<6161 5434 5073 5043 5037>,
			<8301 6635 5569 5057 5018>,
			<5011 10746 8359 5893 5061>,
			<5017 5012 17064 13865 7478>,
			<5080 5023 5016 40489 46065>,
			<14639 5117 5033 5029 40489>,
			<46065 14639 5117 5033 5029>,
			<40489 46065 14639 5117 5033>,
			<5029>;
	};
};
